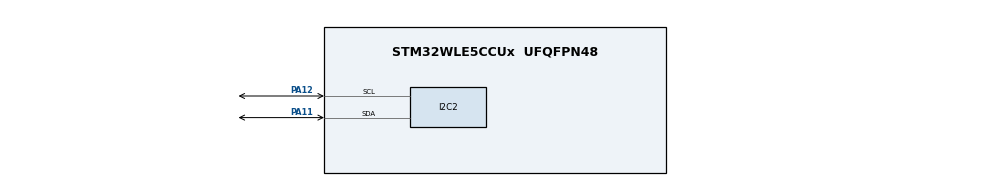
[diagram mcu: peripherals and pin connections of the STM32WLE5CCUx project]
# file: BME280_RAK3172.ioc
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I2C2.Timing=0x10805D88
Mcu.Family=STM32WL
Mcu.Name=STM32WLE5CCUx
Mcu.Package=UFQFPN48
NVIC.PriorityGroup=NVIC_PRIORITYGROUP_4
OSC_IN.Mode=HSE-External-Oscillator
OSC_IN.Signal=RCC_OSC_IN
OSC_OUT.Mode=HSE-External-Oscillator
OSC_OUT.Signal=RCC_OSC_OUT
PA11.Mode=I2C
PA11.Signal=I2C2_SDA
PA12.Mode=I2C
PA12.Signal=I2C2_SCL
PA13.Signal=DEBUG_JTMS-SWDIO
PA14.Signal=DEBUG_JTCK-SWCLK
PC14-OSC32_IN.Mode=LSE-External-Oscillator
PC14-OSC32_IN.Signal=RCC_OSC32_IN
PC15-OSC32_OUT.Mode=LSE-External-Oscillator
PC15-OSC32_OUT.Signal=RCC_OSC32_OUT
ProjectManager.HeapSize=0x200
ProjectManager.StackSize=0x400
ProjectManager.TargetToolchain=STM32CubeIDE
RCC.AHBFreq_Value=48000000
RCC.APB1Freq_Value=48000000
RCC.APB1TimFreq_Value=48000000
RCC.APB2Freq_Value=48000000
RCC.APB2TimFreq_Value=48000000
RCC.APB3Freq_Value=48000000
RCC.CortexFreq_Value=48000000
RCC.FLatency=FLASH_LATENCY_2
RCC.HCLKFreq_Value=48000000
RCC.HSE_VALUE=8000000
RCC.HSI_VALUE=16000000
RCC.LSE_VALUE=32768
RCC.MSIClockRange=RCC_MSIRANGE_11
RCC.PWR_Regulator_Voltage_Scale=PWR_REGULATOR_VOLTAGE_SCALE1
RCC.SYSCLKFreq_VALUE=48000000
RCC.VCOOutputFreq_Value=384000000
board=custom

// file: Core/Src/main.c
/* USER CODE BEGIN Header */
/**
  ******************************************************************************
  * @file           : main.c
  * @brief          : Main program body
  ******************************************************************************
  * @attention
  *
  * Copyright (c) 2025 STMicroelectronics.
  * All rights reserved.
  *
  * This software is licensed under terms that can be found in the LICENSE file
  * in the root directory of this software component.
  * If no LICENSE file comes with this software, it is provided AS-IS.
  *
  ******************************************************************************
  */
/* USER CODE END Header */
#include "main.h"
#include "i2c.h"
#include "gpio.h"

/* USER CODE BEGIN Includes */
#include "app_bme280.h"
/* USER CODE END Includes */

void SystemClock_Config(void);
/* USER CODE BEGIN PFP */
extern void initialize_bme280_sensor(void);
/* USER CODE END PFP */

/* USER CODE BEGIN 0 */
extern void initialise_monitor_handles(void);
/* USER CODE END 0 */

int main(void)
{

  /* USER CODE BEGIN 1 */
	initialise_monitor_handles();
  /* USER CODE END 1 */

  /* MCU Configuration--------------------------------------------------------*/

  /* Reset of all peripherals, Initializes the Flash interface and the Systick. */
  HAL_Init();

  /* Configure the system clock */
  SystemClock_Config();

  /* Initialize all configured peripherals */
  MX_GPIO_Init();
  MX_I2C2_Init();
  /* USER CODE BEGIN 2 */
  initialize_bme280_sensor();
  /* USER CODE END 2 */

  /* Infinite loop */
  while (1)
  {

    /* USER CODE BEGIN 3 */
    sensor_data_acquisition();
  }
  /* USER CODE END 3 */
}

void SystemClock_Config(void)
{
  RCC_OscInitTypeDef RCC_OscInitStruct = {0};
  RCC_ClkInitTypeDef RCC_ClkInitStruct = {0};

  /** Configure LSE Drive Capability
  */
  HAL_PWR_EnableBkUpAccess();
  __HAL_RCC_LSEDRIVE_CONFIG(RCC_LSEDRIVE_LOW);

  /** Configure the main internal regulator output voltage
  */
  __HAL_PWR_VOLTAGESCALING_CONFIG(PWR_REGULATOR_VOLTAGE_SCALE1);

  /** Initializes the CPU, AHB and APB buses clocks
  */
  RCC_OscInitStruct.OscillatorType = RCC_OSCILLATORTYPE_LSE|RCC_OSCILLATORTYPE_MSI;
  RCC_OscInitStruct.LSEState = RCC_LSE_ON;
  RCC_OscInitStruct.MSIState = RCC_MSI_ON;
  RCC_OscInitStruct.MSICalibrationValue = RCC_MSICALIBRATION_DEFAULT;
  RCC_OscInitStruct.MSIClockRange = RCC_MSIRANGE_11;
  RCC_OscInitStruct.PLL.PLLState = RCC_PLL_NONE;
  if (HAL_RCC_OscConfig(&RCC_OscInitStruct) != HAL_OK)
  {
    Error_Handler();
  }

  /** Configure the SYSCLKSource, HCLK, PCLK1 and PCLK2 clocks dividers
  */
  RCC_ClkInitStruct.ClockType = RCC_CLOCKTYPE_HCLK3|RCC_CLOCKTYPE_HCLK
                              |RCC_CLOCKTYPE_SYSCLK|RCC_CLOCKTYPE_PCLK1
                              |RCC_CLOCKTYPE_PCLK2;
  RCC_ClkInitStruct.SYSCLKSource = RCC_SYSCLKSOURCE_MSI;
  RCC_ClkInitStruct.AHBCLKDivider = RCC_SYSCLK_DIV1;
  RCC_ClkInitStruct.APB1CLKDivider = RCC_HCLK_DIV1;
  RCC_ClkInitStruct.APB2CLKDivider = RCC_HCLK_DIV1;
  RCC_ClkInitStruct.AHBCLK3Divider = RCC_SYSCLK_DIV1;

  if (HAL_RCC_ClockConfig(&RCC_ClkInitStruct, FLASH_LATENCY_2) != HAL_OK)
  {
    Error_Handler();
  }
}

void Error_Handler(void)
{
  __disable_irq();
  while (1)
  {
  }
}
